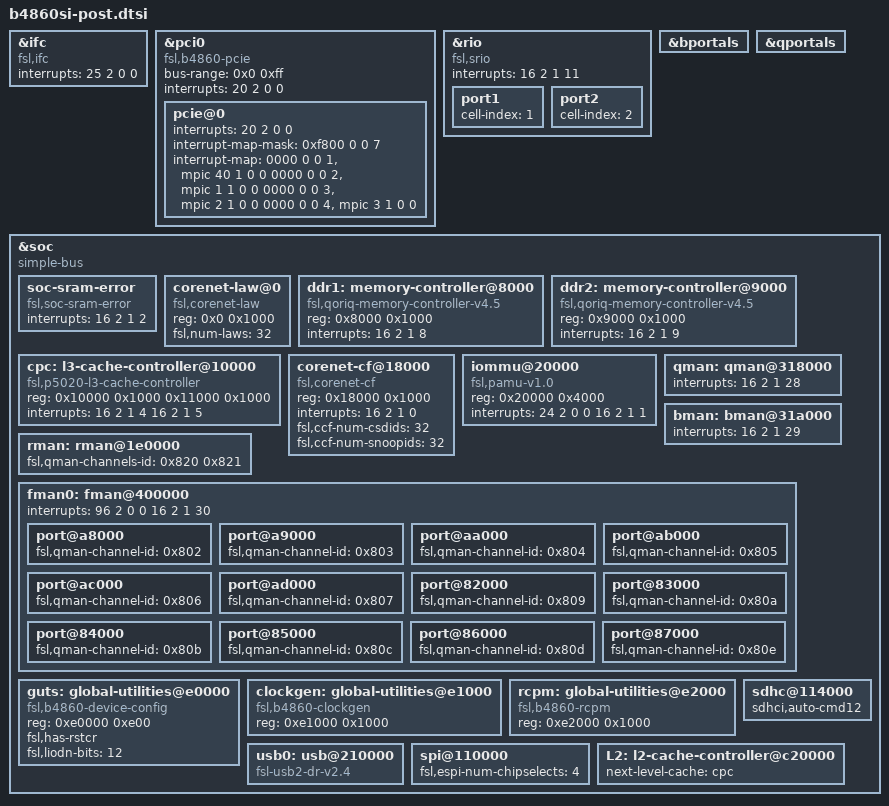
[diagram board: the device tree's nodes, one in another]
/*
 * B4860 Silicon/SoC Device Tree Source (post include)
 *
 * Copyright 2012 Freescale Semiconductor Inc.
 *
 * Redistribution and use in source and binary forms, with or without
 * modification, are permitted provided that the following conditions are met:
 *     * Redistributions of source code must retain the above copyright
 *       notice, this list of conditions and the following disclaimer.
 *     * Redistributions in binary form must reproduce the above copyright
 *       notice, this list of conditions and the following disclaimer in the
 *       documentation and/or other materials provided with the distribution.
 *     * Neither the name of Freescale Semiconductor nor the
 *       names of its contributors may be used to endorse or promote products
 *       derived from this software without specific prior written permission.
 *
 *
 * ALTERNATIVELY, this software may be distributed under the terms of the
 * GNU General Public License ("GPL") as published by the Free Software
 * Foundation, either version 2 of that License or (at your option) any
 * later version.
 *
 * THIS SOFTWARE IS PROVIDED BY Freescale Semiconductor ``AS IS'' AND ANY
 * EXPRESS OR IMPLIED WARRANTIES, INCLUDING, BUT NOT LIMITED TO, THE IMPLIED
 * WARRANTIES OF MERCHANTABILITY AND FITNESS FOR A PARTICULAR PURPOSE ARE
 * DISCLAIMED. IN NO EVENT SHALL Freescale Semiconductor BE LIABLE FOR ANY
 * DIRECT, INDIRECT, INCIDENTAL, SPECIAL, EXEMPLARY, OR CONSEQUENTIAL DAMAGES
 * (INCLUDING, BUT NOT LIMITED TO, PROCUREMENT OF SUBSTITUTE GOODS OR SERVICES;
 * LOSS OF USE, DATA, OR PROFITS; OR BUSINESS INTERRUPTION) HOWEVER CAUSED AND
 * ON ANY THEORY OF LIABILITY, WHETHER IN CONTRACT, STRICT LIABILITY, OR TORT
 * (INCLUDING NEGLIGENCE OR OTHERWISE) ARISING IN ANY WAY OUT OF THE USE OF THIS
 * SOFTWARE, EVEN IF ADVISED OF THE POSSIBILITY OF SUCH DAMAGE.
 */

&ifc {
	#address-cells = <2>;
	#size-cells = <1>;
	compatible = "fsl,ifc", "simple-bus";
	interrupts = <25 2 0 0>;
};

/* controller at 0x200000 */
&pci0 {
	compatible = "fsl,b4860-pcie", "fsl,qoriq-pcie-v2.4";
	device_type = "pci";
	#size-cells = <2>;
	#address-cells = <3>;
	bus-range = <0x0 0xff>;
	interrupts = <20 2 0 0>;
	pcie@0 {
		#interrupt-cells = <1>;
		#size-cells = <2>;
		#address-cells = <3>;
		device_type = "pci";
		interrupts = <20 2 0 0>;
		interrupt-map-mask = <0xf800 0 0 7>;
		interrupt-map = <
			/* IDSEL 0x0 */
			0000 0 0 1 &mpic 40 1 0 0
			0000 0 0 2 &mpic 1 1 0 0
			0000 0 0 3 &mpic 2 1 0 0
			0000 0 0 4 &mpic 3 1 0 0
			>;
	};
};

&rio {
	compatible = "fsl,srio";
	interrupts = <16 2 1 11>;
	#address-cells = <2>;
	#size-cells = <2>;
	ranges;

	port1 {
		#address-cells = <2>;
		#size-cells = <2>;
		cell-index = <1>;
	};

	port2 {
		#address-cells = <2>;
		#size-cells = <2>;
		cell-index = <2>;
	};
};

&bportals {
/include/ "qoriq-bman2-portals.dtsi"
};
&qportals {
/include/ "qoriq-qman2-portals.dtsi"
};

&soc {
	#address-cells = <1>;
	#size-cells = <1>;
	device_type = "soc";
	compatible = "simple-bus";

	soc-sram-error {
		compatible = "fsl,soc-sram-error";
		interrupts = <16 2 1 2>;
	};

	corenet-law@0 {
		compatible = "fsl,corenet-law";
		reg = <0x0 0x1000>;
		fsl,num-laws = <32>;
	};

	ddr1: memory-controller@8000 {
		compatible = "fsl,qoriq-memory-controller-v4.5", "fsl,qoriq-memory-controller";
		reg = <0x8000 0x1000>;
		interrupts = <16 2 1 8>;
	};

	ddr2: memory-controller@9000 {
		compatible = "fsl,qoriq-memory-controller-v4.5","fsl,qoriq-memory-controller";
		reg = <0x9000 0x1000>;
		interrupts = <16 2 1 9>;
	};

	cpc: l3-cache-controller@10000 {
		compatible = "fsl,p5020-l3-cache-controller", "fsl,p4080-l3-cache-controller", "cache";
		reg = <0x10000 0x1000
		       0x11000 0x1000>;
		interrupts = <16 2 1 4
			      16 2 1 5>;
	};

	corenet-cf@18000 {
		compatible = "fsl,corenet-cf";
		reg = <0x18000 0x1000>;
		interrupts = <16 2 1 0>;
		fsl,ccf-num-csdids = <32>;
		fsl,ccf-num-snoopids = <32>;
	};

	iommu@20000 {
		compatible = "fsl,pamu-v1.0", "fsl,pamu";
		reg = <0x20000 0x4000>;
		interrupts = <
			24 2 0 0
			16 2 1 1>;
	};

/include/ "qoriq-qman1.dtsi"

	qman: qman@318000 {
		interrupts = <16 2 1 28>;
	};

/include/ "qoriq-bman1.dtsi"

	bman: bman@31a000 {
		interrupts = <16 2 1 29>;
	};

/include/ "qoriq-rman-0.dtsi"
	rman: rman@1e0000 {
		fsl,qman-channels-id = <0x820 0x821>;
	};

/include/ "qoriq-fman3-0.dtsi"
/include/ "qoriq-fman3-0-1g-0.dtsi"
/include/ "qoriq-fman3-0-1g-1.dtsi"
/include/ "qoriq-fman3-0-1g-2.dtsi"
/include/ "qoriq-fman3-0-1g-3.dtsi"
/include/ "qoriq-fman3-0-1g-4.dtsi"
/include/ "qoriq-fman3-0-1g-5.dtsi"
	fman0: fman@400000 {
		interrupts = <
			96 2 0 0
			16 2 1 30>;

		/* tx - 1g - 0 */
		port@a8000 {
			fsl,qman-channel-id = <0x802>;
		};
		/* tx - 1g - 1 */
		port@a9000 {
			fsl,qman-channel-id = <0x803>;
		};
		/* tx - 1g - 2 */
		port@aa000 {
			fsl,qman-channel-id = <0x804>;
		};
		/* tx - 1g - 3 */
		port@ab000 {
			fsl,qman-channel-id = <0x805>;
		};
		/* tx - 1g - 4 */
		port@ac000 {
			fsl,qman-channel-id = <0x806>;
		};
		/* tx - 1g - 5 */
		port@ad000 {
			fsl,qman-channel-id = <0x807>;
		};
		/* offline - 0 is not usable on B4860 */
		/* offline - 1 */
		port@82000 {
			fsl,qman-channel-id = <0x809>;
		};
		/* offline - 2 */
		port@83000 {
			fsl,qman-channel-id = <0x80a>;
		};
		/* offline - 3 */
		port@84000 {
			fsl,qman-channel-id = <0x80b>;
		};
		/* offline - 4 */
		port@85000 {
			fsl,qman-channel-id = <0x80c>;
		};
		/* offline - 5 */
		port@86000 {
			fsl,qman-channel-id = <0x80d>;
		};
		/* offline - 6 */
		port@87000 {
			fsl,qman-channel-id = <0x80e>;
		};
	};

/include/ "qoriq-mpic.dtsi"

	guts: global-utilities@e0000 {
		compatible = "fsl,b4860-device-config";
		reg = <0xe0000 0xe00>;
		fsl,has-rstcr;
		fsl,liodn-bits = <12>;
	};

	clockgen: global-utilities@e1000 {
		compatible = "fsl,b4860-clockgen", "fsl,qoriq-clockgen-2";
		reg = <0xe1000 0x1000>;
	};

	rcpm: global-utilities@e2000 {
		compatible = "fsl,b4860-rcpm", "fsl,qoriq-rcpm-2";
		reg = <0xe2000 0x1000>;
	};

/include/ "qoriq-dma-0.dtsi"
/include/ "qoriq-dma-1.dtsi"

/include/ "qonverge-usb2-dr-0.dtsi"
	usb0: usb@210000 {
		compatible = "fsl-usb2-dr-v2.4", "fsl-usb2-dr";
	};

/include/ "qoriq-espi-0.dtsi"
	spi@110000 {
		fsl,espi-num-chipselects = <4>;
	};

/include/ "qoriq-esdhc-0.dtsi"
	sdhc@114000 {
		sdhci,auto-cmd12;
	};
/include/ "qoriq-i2c-0.dtsi"
/include/ "qoriq-i2c-1.dtsi"
/include/ "qoriq-duart-0.dtsi"
/include/ "qoriq-duart-1.dtsi"
/include/ "qoriq-sec5.3-0.dtsi"

	L2: l2-cache-controller@c20000 {
		next-level-cache = <&cpc>;
	};
};
